# Montana register map
Vendor: ONSemiconductor; Series: Montana Series; File version: 1.0
CPU: CM33 r0p4, little endian, MPU, FPU, 3 interrupt priority bits
Registers are 32-bit, read-write, reset 0x0 unless marked. A register's access mark holds for its fields unless they carry their own. Offsets are from the block's base; [hi:lo] are bit positions; {n}, {i} and the like mark numbered series.

## GPIO — GPIO Interface and Digital Pad control
Base 0x40000A00
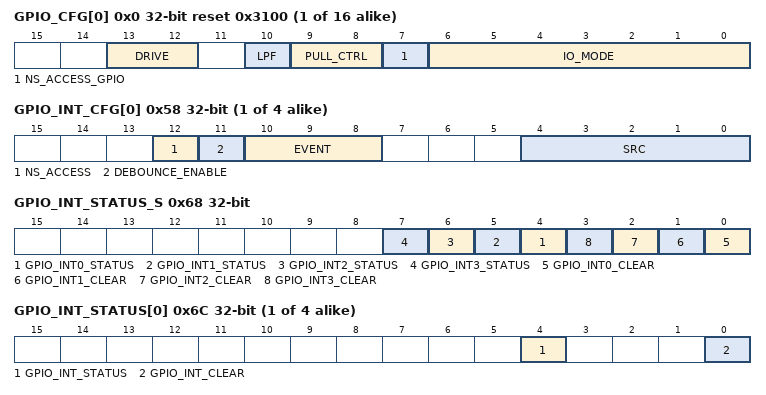
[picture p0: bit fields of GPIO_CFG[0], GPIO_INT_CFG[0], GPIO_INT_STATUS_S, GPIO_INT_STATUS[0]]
{0x0+4i} GPIO_CFG[{i}] (i=0..15) reset 0x3100 — Digital IO Configuration
  [13:12] DRIVE — Drive strength configuration
    0=GPIO_2X_DRIVE (2x drive strength); 1=GPIO_3X_DRIVE (3x drive strength); 2=GPIO_5X_DRIVE (5x drive strength); 3=GPIO_6X_DRIVE (6x drive strength)
  [10] LPF — Low Pass Filter enable
    0=GPIO_LPF_DISABLE (Disable low pass filter); 1=GPIO_LPF_ENABLE (Enable low pass filter)
  [9:8] PULL_CTRL — Pull selection
    0=GPIO_NO_PULL (No pull selected); 1=GPIO_WEAK_PULL_UP (Weak pull-up selected); 2=GPIO_WEAK_PULL_DOWN (Weak pull-down selected); 3=GPIO_STRONG_PULL_UP (Strong pull-up selected)
  [7] NS_ACCESS_GPIO — Non-Secure code can use GPIO
    0=NS_CANNOT_USE_GPIO (Non-Secure code cannot use this GPIO); 1=NS_CAN_USE_GPIO (Non-Secure code can use this GPIO)
  [6:0] IO_MODE — IO mode selection
    0=GPIO_MODE_DISABLE (Disable); 1=GPIO_MODE_INPUT (Input mode); 2=GPIO_MODE_GPIO_IN (GPIO input mode); 3=GPIO_MODE_GPIO_OUT (GPIO output mode (value given by GPIO_OUTPUT_DATA register)); 4=GPIO_MODE_SLOWCLK (Output SLOWCLK (slow clock) signal); 5=GPIO_MODE_SYSCLK (Output SYSCLK (system clock) signal); 6=GPIO_MODE_USRCLK (Output USRCLK (user clock) signal); 7=GPIO_MODE_SPI0_IO0 (Output SPI0_IO0 interface signal (master SERO)); 8=GPIO_MODE_SPI0_IO1 (Output SPI0_IO1 interface signal (slave SERO)); 9=GPIO_MODE_SPI0_IO2 (Output SPI0_IO2 interface signal); 10=GPIO_MODE_SPI0_IO3 (Output SPI0_IO3 interface signal); 11=GPIO_MODE_SPI0_CS (Output SPI0_CS interface signal); 12=GPIO_MODE_SPI0_CLK (Output SPI0_CLK interface signal); 13=GPIO_MODE_UART0_TX (Output UART0_TX0 interface signal); 14=GPIO_MODE_I2C0_SCL (Output I2C0 SCL interface signal (open collector)); 15=GPIO_MODE_I2C0_SDA (Output I2C0 SDA interface signal (open collector)); 16=GPIO_MODE_RFCLK (Output RFCLK signal); 17=GPIO_MODE_RCCLK (Output RCCLK signal); 18=GPIO_MODE_SWCLK_DIV (Output of SWCLK divider signal); 19=GPIO_MODE_STANDBYCLK (Output STANDBYCLK signal); 20=GPIO_MODE_BB_TX_DATA (Output baseband controller TX data signal); 21=GPIO_MODE_BB_TX_DATA_VALID (Output baseband controller TX data valid signal); 22=GPIO_MODE_BB_SPI_CSN (Output baseband controller SPI_CSN signal); 23=GPIO_MODE_BB_SPI_CLK (Output baseband controller SPI_CLK signal); 24=GPIO_MODE_BB_SPI_MOSI (Output baseband controller SPI_MOSI signal); {v}=GPIO_MODE_BB_DBG_{v-25} (Output baseband controller debug port (bit {v-25}) signal) (v=25..32); 33=GPIO_MODE_BB_BLE_SYNC (Output baseband controller wlan coex signal sync); 34=GPIO_MODE_BB_BLE_IN_PROCESS (Output baseband controller wlan coex signal in_process); 35=GPIO_MODE_BB_BLE_TX (Output baseband controller wlan coex signal Tx); 36=GPIO_MODE_BB_BLE_RX (Output baseband controller wlan coex signal Rx); {v}=GPIO_MODE_BB_BLE_PTI_{v-37} (Output baseband controller wlan coex signal PTI (bit {v-37})) (v=37..40); 41=GPIO_MODE_BB_ANT_SW_EN (Output baseband controller antenna switch enable); {v}=GPIO_MODE_BB_ANT_SW_{v-42} (Output baseband controller antenna switch (bit {v-42})) (v=42..48); 49=GPIO_MODE_BB_CTE_MODE (Output baseband controller CTE mode); 50=GPIO_MODE_BB_CTE_SAMPLE_P (Output baseband controller CTE sample pulse); 51=GPIO_MODE_RF_SPI_MISO (Output RF front-end SPI_MISO interface signal); 52=GPIO_MODE_RF_GPIO0 (Output RF front-end GPIO0 output signal (RX_DATA)); 53=GPIO_MODE_RF_GPIO1 (Output RF front-end GPIO1 output signal (RX_CLK)); 54=GPIO_MODE_RF_GPIO2 (Output RF front-end GPIO2 output signal (SYNC_P)); {v}=GPIO_MODE_RF_GPIO{v-52} (Output RF front-end GPIO{v-52} output signal) (v=55..61); 62=GPIO_MODE_RF_IQ_DATA_P (Output RF front-end IQ data pulse signal); {v}=GPIO_MODE_RF_I_DATA_{v-63} (Output RF front-end I data (bit {v-63})) (v=63..70); {v}=GPIO_MODE_RF_Q_DATA_{v-71} (Output RF front-end Q data (bit {v-71})) (v=71..78); {v}=GPIO_MODE_RF_ANT_SW_{v-79} (Output RF front-end antenna switch (bit {v-79})) (v=79..82); 83=GPIO_MODE_TOF_START (Output Time Of Flight timer start trigger); 84=GPIO_MODE_TOF_STOP (Output Time Of Flight timer stop trigger)
0x40 GPIO_INPUT_DATA ro — Digital IOs Input Data State
  [15:0] DATA — GPIO[15:0] read data
    0=GPIO0_IN_LOW (GPIO pad is low); 0=GPIO1_IN_LOW (GPIO pad is low); 0=GPIO2_IN_LOW (GPIO pad is low); 0=GPIO3_IN_LOW (GPIO pad is low); 0=GPIO4_IN_LOW (GPIO pad is low); 0=GPIO5_IN_LOW (GPIO pad is low); 0=GPIO6_IN_LOW (GPIO pad is low); 0=GPIO7_IN_LOW (GPIO pad is low); 0=GPIO8_IN_LOW (GPIO pad is low); 0=GPIO9_IN_LOW (GPIO pad is low); 0=GPIO10_IN_LOW (GPIO pad is low); 0=GPIO11_IN_LOW (GPIO pad is low); 0=GPIO12_IN_LOW (GPIO pad is low); 0=GPIO13_IN_LOW (GPIO pad is low); 0=GPIO14_IN_LOW (GPIO pad is low); 0=GPIO15_IN_LOW (GPIO pad is low); 1=GPIO0_IN_HIGH (GPIO pad is high); 2=GPIO1_IN_HIGH (GPIO pad is high); 4=GPIO2_IN_HIGH (GPIO pad is high); 8=GPIO3_IN_HIGH (GPIO pad is high); 16=GPIO4_IN_HIGH (GPIO pad is high); 32=GPIO5_IN_HIGH (GPIO pad is high); 64=GPIO6_IN_HIGH (GPIO pad is high); 128=GPIO7_IN_HIGH (GPIO pad is high); 0x100=GPIO8_IN_HIGH (GPIO pad is high); 0x200=GPIO9_IN_HIGH (GPIO pad is high); 0x400=GPIO10_IN_HIGH (GPIO pad is high); 0x800=GPIO11_IN_HIGH (GPIO pad is high); 0x1000=GPIO12_IN_HIGH (GPIO pad is high); 0x2000=GPIO13_IN_HIGH (GPIO pad is high); 0x4000=GPIO14_IN_HIGH (GPIO pad is high); 0x8000=GPIO15_IN_HIGH (GPIO pad is high)
0x44 GPIO_OUTPUT_DATA
  [15:0] DATA — GPIO[15:0] output data
    0=GPIO0_OUT_LOW (Set the GPIO pad to low if IO_MODE is GPIO); 0=GPIO1_OUT_LOW (Set the GPIO pad to low if IO_MODE is GPIO); 0=GPIO2_OUT_LOW (Set the GPIO pad to low if IO_MODE is GPIO); 0=GPIO3_OUT_LOW (Set the GPIO pad to low if IO_MODE is GPIO); 0=GPIO4_OUT_LOW (Set the GPIO pad to low if IO_MODE is GPIO); 0=GPIO5_OUT_LOW (Set the GPIO pad to low if IO_MODE is GPIO); 0=GPIO6_OUT_LOW (Set the GPIO pad to low if IO_MODE is GPIO); 0=GPIO7_OUT_LOW (Set the GPIO pad to low if IO_MODE is GPIO); 0=GPIO8_OUT_LOW (Set the GPIO pad to low if IO_MODE is GPIO); 0=GPIO9_OUT_LOW (Set the GPIO pad to low if IO_MODE is GPIO); 0=GPIO10_OUT_LOW (Set the GPIO pad to low if IO_MODE is GPIO); 0=GPIO11_OUT_LOW (Set the GPIO pad to low if IO_MODE is GPIO); 0=GPIO12_OUT_LOW (Set the GPIO pad to low if IO_MODE is GPIO); 0=GPIO13_OUT_LOW (Set the GPIO pad to low if IO_MODE is GPIO); 0=GPIO14_OUT_LOW (Set the GPIO pad to low if IO_MODE is GPIO); 0=GPIO15_OUT_LOW (Set the GPIO pad to low if IO_MODE is GPIO); 1=GPIO0_OUT_HIGH (Set the GPIO pad to high if IO_MODE is GPIO); 2=GPIO1_OUT_HIGH (Set the GPIO pad to high if IO_MODE is GPIO); 4=GPIO2_OUT_HIGH (Set the GPIO pad to high if IO_MODE is GPIO); 8=GPIO3_OUT_HIGH (Set the GPIO pad to high if IO_MODE is GPIO); 16=GPIO4_OUT_HIGH (Set the GPIO pad to high if IO_MODE is GPIO); 32=GPIO5_OUT_HIGH (Set the GPIO pad to high if IO_MODE is GPIO); 64=GPIO6_OUT_HIGH (Set the GPIO pad to high if IO_MODE is GPIO); 128=GPIO7_OUT_HIGH (Set the GPIO pad to high if IO_MODE is GPIO); 0x100=GPIO8_OUT_HIGH (Set the GPIO pad to high if IO_MODE is GPIO); 0x200=GPIO9_OUT_HIGH (Set the GPIO pad to high if IO_MODE is GPIO); 0x400=GPIO10_OUT_HIGH (Set the GPIO pad to high if IO_MODE is GPIO); 0x800=GPIO11_OUT_HIGH (Set the GPIO pad to high if IO_MODE is GPIO); 0x1000=GPIO12_OUT_HIGH (Set the GPIO pad to high if IO_MODE is GPIO); 0x2000=GPIO13_OUT_HIGH (Set the GPIO pad to high if IO_MODE is GPIO); 0x4000=GPIO14_OUT_HIGH (Set the GPIO pad to high if IO_MODE is GPIO); 0x8000=GPIO15_OUT_HIGH (Set the GPIO pad to high if IO_MODE is GPIO)
0x48 GPIO_OUTPUT_DATA_SET reset not defined
  [15:0] GPIO wo — GPIO[15:0] output data set
    1=GPIO0_SET (Set the GPIO output data high); 2=GPIO1_SET (Set the GPIO output data high); 4=GPIO2_SET (Set the GPIO output data high); 8=GPIO3_SET (Set the GPIO output data high); 16=GPIO4_SET (Set the GPIO output data high); 32=GPIO5_SET (Set the GPIO output data high); 64=GPIO6_SET (Set the GPIO output data high); 128=GPIO7_SET (Set the GPIO output data high); 0x100=GPIO8_SET (Set the GPIO output data high); 0x200=GPIO9_SET (Set the GPIO output data high); 0x400=GPIO10_SET (Set the GPIO output data high); 0x800=GPIO11_SET (Set the GPIO output data high); 0x1000=GPIO12_SET (Set the GPIO output data high); 0x2000=GPIO13_SET (Set the GPIO output data high); 0x4000=GPIO14_SET (Set the GPIO output data high); 0x8000=GPIO15_SET (Set the GPIO output data high)
0x4C GPIO_OUTPUT_DATA_CLR reset not defined — GPIO Output Data Clear
  [15:0] GPIO wo — GPIO[15:0] output data clear
    1=GPIO0_CLR (Set the GPIO output data low); 2=GPIO1_CLR (Set the GPIO output data low); 4=GPIO2_CLR (Set the GPIO output data low); 8=GPIO3_CLR (Set the GPIO output data low); 16=GPIO4_CLR (Set the GPIO output data low); 32=GPIO5_CLR (Set the GPIO output data low); 64=GPIO6_CLR (Set the GPIO output data low); 128=GPIO7_CLR (Set the GPIO output data low); 0x100=GPIO8_CLR (Set the GPIO output data low); 0x200=GPIO9_CLR (Set the GPIO output data low); 0x400=GPIO10_CLR (Set the GPIO output data low); 0x800=GPIO11_CLR (Set the GPIO output data low); 0x1000=GPIO12_CLR (Set the GPIO output data low); 0x2000=GPIO13_CLR (Set the GPIO output data low); 0x4000=GPIO14_CLR (Set the GPIO output data low); 0x8000=GPIO15_CLR (Set the GPIO output data low)
0x50 GPIO_DIR — Digital IOs Direction State
  [15:0] GPIO ro — Get GPIO[15:0] direction
    0=GPIO0_STATUS_IN (GPIO is an input); 0=GPIO1_STATUS_IN (GPIO is an input); 0=GPIO2_STATUS_IN (GPIO is an input); 0=GPIO3_STATUS_IN (GPIO is an input); 0=GPIO4_STATUS_IN (GPIO is an input); 0=GPIO5_STATUS_IN (GPIO is an input); 0=GPIO6_STATUS_IN (GPIO is an input); 0=GPIO7_STATUS_IN (GPIO is an input); 0=GPIO8_STATUS_IN (GPIO is an input); 0=GPIO9_STATUS_IN (GPIO is an input); 0=GPIO10_STATUS_IN (GPIO is an input); 0=GPIO11_STATUS_IN (GPIO is an input); 0=GPIO12_STATUS_IN (GPIO is an input); 0=GPIO13_STATUS_IN (GPIO is an input); 0=GPIO14_STATUS_IN (GPIO is an input); 0=GPIO15_STATUS_IN (GPIO is an input); 1=GPIO0_STATUS_OUT (GPIO is an output); 2=GPIO1_STATUS_OUT (GPIO is an output); 4=GPIO2_STATUS_OUT (GPIO is an output); 8=GPIO3_STATUS_OUT (GPIO is an output); 16=GPIO4_STATUS_OUT (GPIO is an output); 32=GPIO5_STATUS_OUT (GPIO is an output); 64=GPIO6_STATUS_OUT (GPIO is an output); 128=GPIO7_STATUS_OUT (GPIO is an output); 0x100=GPIO8_STATUS_OUT (GPIO is an output); 0x200=GPIO9_STATUS_OUT (GPIO is an output); 0x400=GPIO10_STATUS_OUT (GPIO is an output); 0x800=GPIO11_STATUS_OUT (GPIO is an output); 0x1000=GPIO12_STATUS_OUT (GPIO is an output); 0x2000=GPIO13_STATUS_OUT (GPIO is an output); 0x4000=GPIO14_STATUS_OUT (GPIO is an output); 0x8000=GPIO15_STATUS_OUT (GPIO is an output)
  [15:0] GPIO wo — Set GPIO[15:0] GPIO direction (only in GPIO_MODE_GPIO_x)
    0=GPIO0_DIR_IN (Set GPIO to input if GPIO_MODE_GPIO_IN_x); 0=GPIO1_DIR_IN (Set GPIO to input if GPIO_MODE_GPIO_IN_x); 0=GPIO2_DIR_IN (Set GPIO to input if GPIO_MODE_GPIO_IN_x); 0=GPIO3_DIR_IN (Set GPIO to input if GPIO_MODE_GPIO_IN_x); 0=GPIO4_DIR_IN (Set GPIO to input if GPIO_MODE_GPIO_IN_x); 0=GPIO5_DIR_IN (Set GPIO to input if GPIO_MODE_GPIO_IN_x); 0=GPIO6_DIR_IN (Set GPIO to input if GPIO_MODE_GPIO_IN_x); 0=GPIO7_DIR_IN (Set GPIO to input if GPIO_MODE_GPIO_IN_x); 0=GPIO8_DIR_IN (Set GPIO to input if GPIO_MODE_GPIO_IN_x); 0=GPIO9_DIR_IN (Set GPIO to input if GPIO_MODE_GPIO_IN_x); 0=GPIO10_DIR_IN (Set GPIO to input if GPIO_MODE_GPIO_IN_x); 0=GPIO11_DIR_IN (Set GPIO to input if GPIO_MODE_GPIO_IN_x); 0=GPIO12_DIR_IN (Set GPIO to input if GPIO_MODE_GPIO_IN_x); 0=GPIO13_DIR_IN (Set GPIO to input if GPIO_MODE_GPIO_IN_x); 0=GPIO14_DIR_IN (Set GPIO to input if GPIO_MODE_GPIO_IN_x); 0=GPIO15_DIR_IN (Set GPIO to input if GPIO_MODE_GPIO_IN_x); 1=GPIO0_DIR_OUT (Set GPIO to output if GPIO_MODE_GPIO_OUT_x); 2=GPIO1_DIR_OUT (Set GPIO to output if GPIO_MODE_GPIO_OUT_x); 4=GPIO2_DIR_OUT (Set GPIO to output if GPIO_MODE_GPIO_OUT_x); 8=GPIO3_DIR_OUT (Set GPIO to output if GPIO_MODE_GPIO_OUT_x); 16=GPIO4_DIR_OUT (Set GPIO to output if GPIO_MODE_GPIO_OUT_x); 32=GPIO5_DIR_OUT (Set GPIO to output if GPIO_MODE_GPIO_OUT_x); 64=GPIO6_DIR_OUT (Set GPIO to output if GPIO_MODE_GPIO_OUT_x); 128=GPIO7_DIR_OUT (Set GPIO to output if GPIO_MODE_GPIO_OUT_x); 0x100=GPIO8_DIR_OUT (Set GPIO to output if GPIO_MODE_GPIO_OUT_x); 0x200=GPIO9_DIR_OUT (Set GPIO to output if GPIO_MODE_GPIO_OUT_x); 0x400=GPIO10_DIR_OUT (Set GPIO to output if GPIO_MODE_GPIO_OUT_x); 0x800=GPIO11_DIR_OUT (Set GPIO to output if GPIO_MODE_GPIO_OUT_x); 0x1000=GPIO12_DIR_OUT (Set GPIO to output if GPIO_MODE_GPIO_OUT_x); 0x2000=GPIO13_DIR_OUT (Set GPIO to output if GPIO_MODE_GPIO_OUT_x); 0x4000=GPIO14_DIR_OUT (Set GPIO to output if GPIO_MODE_GPIO_OUT_x); 0x8000=GPIO15_DIR_OUT (Set GPIO to output if GPIO_MODE_GPIO_OUT_x)
0x54 GPIO_MODE ro — Digital IOs Mode State
  [15:0] GPIO — GPIO[15:0] mode
    0=GPIO0_IS_NOT_GPIO_MODE (This GPIO is not configured as a CM33 controlled GPIO); 0=GPIO1_IS_NOT_GPIO_MODE (This GPIO is not configured as a CM33 controlled GPIO); 0=GPIO2_IS_NOT_GPIO_MODE (This GPIO is not configured as a CM33 controlled GPIO); 0=GPIO3_IS_NOT_GPIO_MODE (This GPIO is not configured as a CM33 controlled GPIO); 0=GPIO4_IS_NOT_GPIO_MODE (This GPIO is not configured as a CM33 controlled GPIO); 0=GPIO5_IS_NOT_GPIO_MODE (This GPIO is not configured as a CM33 controlled GPIO); 0=GPIO6_IS_NOT_GPIO_MODE (This GPIO is not configured as a CM33 controlled GPIO); 0=GPIO7_IS_NOT_GPIO_MODE (This GPIO is not configured as a CM33 controlled GPIO); 0=GPIO8_IS_NOT_GPIO_MODE (This GPIO is not configured as a CM33 controlled GPIO); 0=GPIO9_IS_NOT_GPIO_MODE (This GPIO is not configured as a CM33 controlled GPIO); 0=GPIO10_IS_NOT_GPIO_MODE (This GPIO is not configured as a CM33 controlled GPIO); 0=GPIO11_IS_NOT_GPIO_MODE (This GPIO is not configured as a CM33 controlled GPIO); 0=GPIO12_IS_NOT_GPIO_MODE (This GPIO is not configured as a CM33 controlled GPIO); 0=GPIO13_IS_NOT_GPIO_MODE (This GPIO is not configured as a CM33 controlled GPIO); 0=GPIO14_IS_NOT_GPIO_MODE (This GPIO is not configured as a CM33 controlled GPIO); 0=GPIO15_IS_NOT_GPIO_MODE (This GPIO is not configured as a CM33 controlled GPIO); 1=GPIO0_IS_GPIO_MODE (This GPIO is configured as a CM33 controlled GPIO); 2=GPIO1_IS_GPIO_MODE (This GPIO is configured as a CM33 controlled GPIO); 4=GPIO2_IS_GPIO_MODE (This GPIO is configured as a CM33 controlled GPIO); 8=GPIO3_IS_GPIO_MODE (This GPIO is configured as a CM33 controlled GPIO); 16=GPIO4_IS_GPIO_MODE (This GPIO is configured as a CM33 controlled GPIO); 32=GPIO5_IS_GPIO_MODE (This GPIO is configured as a CM33 controlled GPIO); 64=GPIO6_IS_GPIO_MODE (This GPIO is configured as a CM33 controlled GPIO); 128=GPIO7_IS_GPIO_MODE (This GPIO is configured as a CM33 controlled GPIO); 0x100=GPIO8_IS_GPIO_MODE (This GPIO is configured as a CM33 controlled GPIO); 0x200=GPIO9_IS_GPIO_MODE (This GPIO is configured as a CM33 controlled GPIO); 0x400=GPIO10_IS_GPIO_MODE (This GPIO is configured as a CM33 controlled GPIO); 0x800=GPIO11_IS_GPIO_MODE (This GPIO is configured as a CM33 controlled GPIO); 0x1000=GPIO12_IS_GPIO_MODE (This GPIO is configured as a CM33 controlled GPIO); 0x2000=GPIO13_IS_GPIO_MODE (This GPIO is configured as a CM33 controlled GPIO); 0x4000=GPIO14_IS_GPIO_MODE (This GPIO is configured as a CM33 controlled GPIO); 0x8000=GPIO15_IS_GPIO_MODE (This GPIO is configured as a CM33 controlled GPIO)
{0x58+4i} GPIO_INT_CFG[{i}] (i=0..3) — GPIO Interrupt Configuration
  [12] NS_ACCESS — Non-Secure code can access this GPIO_INT
    0=NS_CANNOT_ACCESS_GPIO_INT (Non-Secure code cannot access the GPIO_INT); 1=NS_CAN_ACCESS_GPIO_INT (Non-Secure code can access the GPIO_INT)
  [11] DEBOUNCE_ENABLE — Interrupt button debounce filter enable/disable
    0=GPIO_DEBOUNCE_DISABLE (Button debounce filter disabled); 1=GPIO_DEBOUNCE_ENABLE (Button debounce filter enabled)
  [10:8] EVENT — Interrupt event configuration
    0=GPIO_EVENT_NONE (Interrupt not triggered); 1=GPIO_EVENT_HIGH_LEVEL (Interrupt triggered on high state); 2=GPIO_EVENT_LOW_LEVEL (Interrupt triggered on low state); 3=GPIO_EVENT_RISING_EDGE (Interrupt triggered on rising edge); 4=GPIO_EVENT_FALLING_EDGE (Interrupt triggered on falling edge); 5=GPIO_EVENT_TRANSITION (Interrupt triggered on any edge)
  [4:0] SRC — Interrupt input selection
    {v}=GPIO_SRC_GPIO_{v} (Select GPIO[{v}] as source) (v=0..15); 16=GPIO_SRC_WAKEUP (Select WAKEUP as source)
0x68 GPIO_INT_STATUS_S (reset mask 0xF0) — GPIO Interrupt Status
  [n+4] GPIO_INT{n}_STATUS ro (n=0..3) — GPIO interrupt {n} status
    0=GPIO_INT{n}_FALSE (Interrupt {n} not triggered); 1=GPIO_INT{n}_TRUE (Interrupt {n} triggered)
  [n] GPIO_INT{n}_CLEAR wo (n=0..3) — GPIO interrupt {n} clear
    1=GPIO_INT{n}_CLEAR (Interrupt {n} clear)
{0x6C+4i} GPIO_INT_STATUS[{i}] (i=0..3) (reset mask 0x10) — GPIO Interrupt Status
  [4] GPIO_INT_STATUS ro — GPIO interrupt status
    0=GPIO_INT_FALSE (Interrupt not triggered); 1=GPIO_INT_TRUE (Interrupt triggered)
  [0] GPIO_INT_CLEAR wo — GPIO interrupt clear
    1=GPIO_INT_CLEAR (Interrupt clear)
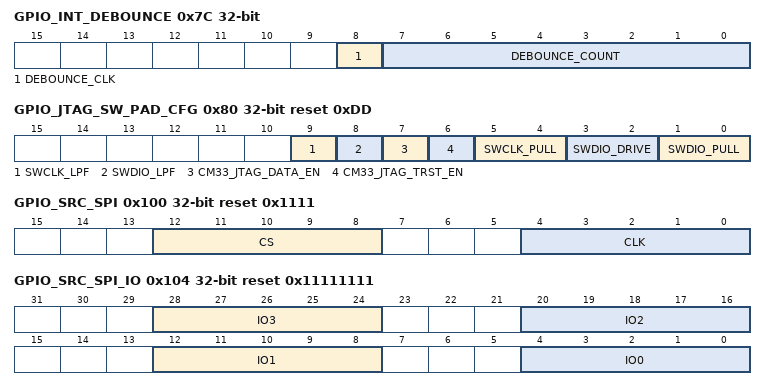
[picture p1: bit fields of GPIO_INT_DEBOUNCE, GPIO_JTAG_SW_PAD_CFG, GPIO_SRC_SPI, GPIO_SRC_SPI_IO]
0x7C GPIO_INT_DEBOUNCE — GPIO Interrupt Button Debounce Filter Time Configuration
  [8] DEBOUNCE_CLK — Interrupt button debounce filter clock
    0=GPIO_DEBOUNCE_SLOWCLK_DIV32 (Button debounce filter runs on SLOWCLK divided by 32); 1=GPIO_DEBOUNCE_SLOWCLK_DIV1024 (Button debounce filter runs on SLOWCLK divided by 1024)
  [7:0] DEBOUNCE_COUNT — Interrupt button debounce filter count
0x80 GPIO_JTAG_SW_PAD_CFG reset 0xDD — JTAG / SW Pad Configuration Register
  [9] SWCLK_LPF — SWCLK Low-Pass-Filter enable / disable
    0=SWCLK_LPF_DISABLED (Disable low pass filter); 1=SWCLK_LPF_ENABLED (Enable low pass filter)
  [8] SWDIO_LPF — SWDIO Low-Pass-Filter enable / disable
    0=SWDIO_LPF_DISABLED (Disable low pass filter); 1=SWDIO_LPF_ENABLED (Enable low pass filter)
  [7] CM33_JTAG_DATA_EN — CM33 JTAG on GPIO[3:2]
    0=CM33_JTAG_DATA_DISABLED (CM33 JTAG data (TDI & TDO) not available on GPIO[3:2]); 1=CM33_JTAG_DATA_ENABLED (CM33 JTAG data (TDI & TDO) connected through GPIO[3:2])
  [6] CM33_JTAG_TRST_EN — CM33 JTAG TRST on GPIO4
    0=CM33_JTAG_TRST_DISABLED (CM33 JTAG TRST not available on GPIO4); 1=CM33_JTAG_TRST_ENABLED (CM33 JTAG TRST connected through GPIO4)
  [5:4] SWCLK_PULL — SWCLK pull-up enable / disable
    0=SWCLK_NO_PULL (No pull selected); 1=SWCLK_WEAK_PULL_UP (Weak pull-up selected); 2=SWCLK_WEAK_PULL_DOWN (Weak pull-down selected); 3=SWCLK_STRONG_PULL_UP (Strong pull-up selected)
  [3:2] SWDIO_DRIVE — SWDIO drive strength
    0=SWDIO_2X_DRIVE (2x drive strength); 1=SWDIO_3X_DRIVE (3x drive strength); 2=SWDIO_5X_DRIVE (5x drive strength); 3=SWDIO_6X_DRIVE (6x drive strength)
  [1:0] SWDIO_PULL — SWDIO pull-up enable / disable
    0=SWDIO_NO_PULL (No pull selected); 1=SWDIO_WEAK_PULL_UP (Weak pull-up selected); 2=SWDIO_WEAK_PULL_DOWN (Weak pull-down selected); 3=SWDIO_STRONG_PULL_UP (Strong pull-up selected)
0x8C GPIO_PAD_CFG — Global Pads Configuration Register
  [0] DRIVE — Drive strength configuration (scales the individual drive strengths)
    0=PAD_LOW_DRIVE (All pad regular drive strengths (allowed for all VDDO voltages)); 1=PAD_HIGH_DRIVE (All pad drive strengths increased by ~50 percent (only allowed for VDDO up to 2.7 V))
0x100 GPIO_SRC_SPI reset 0x1111 — SPI Interface Input Selection
  [12:8] CS — SPI_CS input selection
    {v}=SPI_CS_SRC_GPIO_{v} (Select GPIO[{v}] as source) (v=0..15); 16=SPI_CS_SRC_CONST_LOW (Select constant low as source); 17=SPI_CS_SRC_CONST_HIGH (Select constant high as source)
  [4:0] CLK — SPI_CLK input selection
    {v}=SPI_CLK_SRC_GPIO_{v} (Select GPIO[{v}] as source) (v=0..15); 16=SPI_CLK_SRC_CONST_LOW (Select constant low as source); 17=SPI_CLK_SRC_CONST_HIGH (Select constant high as source)
0x104 GPIO_SRC_SPI_IO reset 0x11111111 — SPI Interface IO Selection
  [28:24] IO3 — SPI_IO3 input selection
    {v}=SPI_IO3_SRC_GPIO_{v} (Select GPIO[{v}] as source) (v=0..15); 16=SPI_IO3_SRC_CONST_LOW (Select constant low as source); 17=SPI_IO3_SRC_CONST_HIGH (Select constant high as source)
  [20:16] IO2 — SPI_IO2 input selection
    {v}=SPI_IO2_SRC_GPIO_{v} (Select GPIO[{v}] as source) (v=0..15); 16=SPI_IO2_SRC_CONST_LOW (Select constant low as source); 17=SPI_IO2_SRC_CONST_HIGH (Select constant high as source)
  [12:8] IO1 — SPI_IO1 input selection (master SERI)
    {v}=SPI_IO1_SRC_GPIO_{v} (Select GPIO[{v}] as source) (v=0..15); 16=SPI_IO1_SRC_CONST_LOW (Select constant low as source); 17=SPI_IO1_SRC_CONST_HIGH (Select constant high as source)
  [4:0] IO0 — SPI_IO0 input selection (slave SERI)
    {v}=SPI_IO0_SRC_GPIO_{v} (Select GPIO[{v}] as source) (v=0..15); 16=SPI_IO0_SRC_CONST_LOW (Select constant low as source); 17=SPI_IO0_SRC_CONST_HIGH (Select constant high as source)
0x108 GPIO_SRC_UART reset 0x11 — UART Interface Input Selection
  [4:0] RX — UART_RX input selection
    {v}=UART_RX_SRC_GPIO_{v} (Select GPIO[{v}] as source) (v=0..15); 16=UART_RX_SRC_CONST_LOW (Select constant low as source); 17=UART_RX_SRC_CONST_HIGH (Select constant high as source)
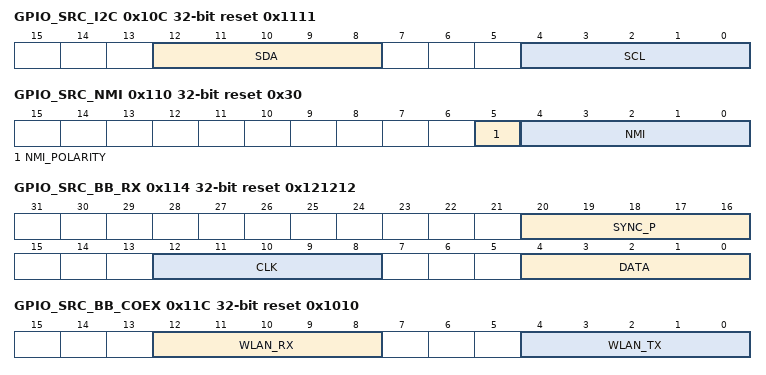
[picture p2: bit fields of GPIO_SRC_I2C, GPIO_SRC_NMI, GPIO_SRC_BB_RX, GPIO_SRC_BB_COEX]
0x10C GPIO_SRC_I2C reset 0x1111 — I2C Input Selection
  [12:8] SDA — SDA input selection
    {v}=I2C_SDA_SRC_GPIO_{v} (Select GPIO[{v}] as source) (v=0..15); 16=I2C_SDA_SRC_CONST_LOW (Select constant low as source); 17=I2C_SDA_SRC_CONST_HIGH (Select constant high as source)
  [4:0] SCL — SCL input selection
    {v}=I2C_SCL_SRC_GPIO_{v} (Select GPIO[{v}] as source) (v=0..15); 16=I2C_SCL_SRC_CONST_LOW (Select constant low as source); 17=I2C_SCL_SRC_CONST_HIGH (Select constant high as source)
0x110 GPIO_SRC_NMI reset 0x30 — NMI Input Selection
  [5] NMI_POLARITY
    0=NMI_ACTIVE_LOW; 1=NMI_ACTIVE_HIGH
  [4:0] NMI — NMI input selection
    {v}=NMI_SRC_GPIO_{v} (Select GPIO[{v}] as source) (v=0..15); 16=NMI_SRC_CONST_LOW (Select constant low as source); 17=NMI_SRC_CONST_HIGH (Select constant high as source)
0x114 GPIO_SRC_BB_RX reset 0x121212 — Baseband controller RX data and clock input selection
  [20:16] SYNC_P — Baseband controller interface SYNC_P input selection
    0=BB_RX_SYNC_P_SRC_GPIO_0 (Select GPIO[0] as source); 1=BB_RX_SYNC_P_SRC_GPIO_1 (Select GPIO[1] as source); 2=BB_RX_SYNC_P_SRC_GPIO_2 (Select GPIO[5] as source); {v}=BB_RX_SYNC_P_SRC_GPIO_{v} (Select GPIO[{v}] as source) (v=3..15); 16=BB_RX_SYNC_P_SRC_CONST_LOW (Select constant low as source); 17=BB_RX_SYNC_P_SRC_CONST_HIGH (Select constant high as source); 18=BB_RX_SYNC_P_SRC_RF_GPIO2 (Select RF front-end GPIO2 output (RX_SYNC_P) as source)
  [12:8] CLK — Baseband controller RX clock input selection
    {v}=BB_RX_CLK_SRC_GPIO_{v} (Select GPIO[{v}] as source) (v=0..15); 16=BB_RX_CLK_SRC_CONST_LOW (Select constant low as source); 17=BB_RX_CLK_SRC_CONST_HIGH (Select constant high as source); 18=BB_RX_CLK_SRC_RF_GPIO1 (Select RF front-end GPIO1 output (RX_CLK) as source)
  [4:0] DATA — Baseband controller RX data input selection
    {v}=BB_RX_DATA_SRC_GPIO_{v} (Select GPIO[{v}] as source) (v=0..15); 16=BB_RX_DATA_SRC_CONST_LOW (Select constant low as source); 17=BB_RX_DATA_SRC_CONST_HIGH (Select constant high as source); 18=BB_RX_DATA_SRC_RF_GPIO0 (Select RF front-end GPIO0 output (RX_DATA) as source)
0x118 GPIO_SRC_BB_SPI reset 0x12 — Baseband controller SPI input selection
  [4:0] MISO — Baseband controller SPI_MISO input selection
    {v}=BB_SPI_MISO_SRC_GPIO_{v} (Select GPIO[{v}] as source) (v=0..15); 16=BB_SPI_MISO_SRC_CONST_LOW (Select constant low as source); 17=BB_SPI_MISO_SRC_CONST_HIGH (Select constant high as source); 18=BB_SPI_MISO_SRC_RF_SPI_MISO (Select RF front-end SPI_MISO as source)
0x11C GPIO_SRC_BB_COEX reset 0x1010 — Baseband controller WLAN coexistence input selection
  [12:8] WLAN_RX — Baseband controller WLAN_RX input selection
    {v}=BB_WLAN_RX_SRC_GPIO_{v} (Select GPIO[{v}] as source) (v=0..15); 16=BB_WLAN_RX_SRC_CONST_LOW (Select constant low as source); 17=BB_WLAN_RX_SRC_CONST_HIGH (Select constant high as source)
  [4:0] WLAN_TX — Baseband controller WLAN_TX input selection
    {v}=BB_WLAN_TX_SRC_GPIO_{v} (Select GPIO[{v}] as source) (v=0..15); 16=BB_WLAN_TX_SRC_CONST_LOW (Select constant low as source); 17=BB_WLAN_TX_SRC_CONST_HIGH (Select constant high as source)
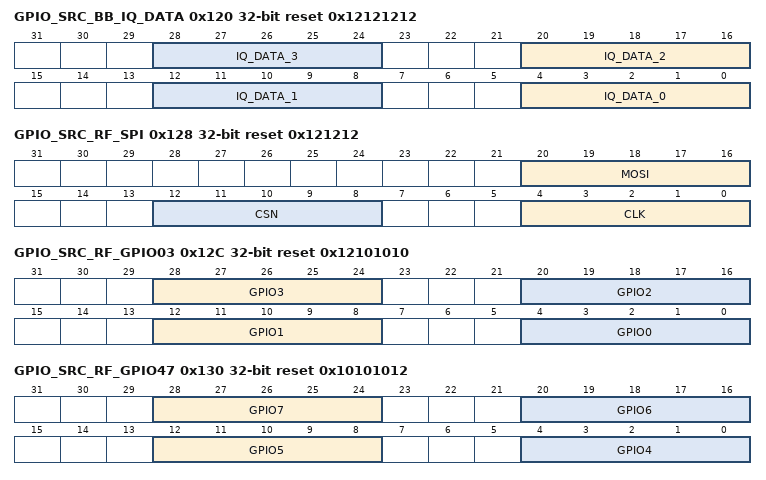
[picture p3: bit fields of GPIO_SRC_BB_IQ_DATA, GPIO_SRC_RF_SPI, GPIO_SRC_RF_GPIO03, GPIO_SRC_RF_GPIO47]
0x120 GPIO_SRC_BB_IQ_DATA reset 0x12121212 — Baseband controller IQ data input selection
  [8n+4:8n] IQ_DATA_{n} (n=0..3) — Baseband controller IQ_DATA_{n} input selection
    {v}=BB_IQ_DATA_{n}_SRC_GPIO_{v} (Select GPIO[{v}] as source) (v=0..15); 16=BB_IQ_DATA_{n}_SRC_CONST_LOW (Select constant low as source); 17=BB_IQ_DATA_{n}_SRC_CONST_HIGH (Select constant high as source); 18=BB_IQ_DATA_{n}_SRC_RF_IQ_DATA_{n} (Select RF front-end IQ_DATA_{n} as source)
0x124 GPIO_SRC_BB_IQ_DATA_P reset 0x12 — Baseband controller IQ data pulse input selection
  [4:0] IQ_DATA_P — Baseband controller IQ_DATA_P input selection
    {v}=BB_IQ_DATA_P_SRC_GPIO_{v} (Select GPIO[{v}] as source) (v=0..15); 16=BB_IQ_DATA_P_SRC_CONST_LOW (Select constant low as source); 17=BB_IQ_DATA_P_SRC_CONST_HIGH (Select constant high as source); 18=BB_IQ_DATA_P_SRC_RF_IQ_DATA_P (Select RF front-end IQ_DATA_P as source)
0x128 GPIO_SRC_RF_SPI reset 0x121212 — RF front-end SPI input selection
  [20:16] MOSI — RF front-end SPI_MOSI input selection
    {v}=RF_SPI_MOSI_SRC_GPIO_{v} (Select GPIO[{v}] as source) (v=0..15); 16=RF_SPI_MOSI_SRC_CONST_LOW (Select constant low as source); 17=RF_SPI_MOSI_SRC_CONST_HIGH (Select constant high as source); 18=RF_SPI_MOSI_SRC_BB_SPI_MOSI (Select baseband controller SPI_MOSI as source)
  [12:8] CSN — RF front-end SPI_CSN input selection
    {v}=RF_SPI_CSN_SRC_GPIO_{v} (Select GPIO[{v}] as source) (v=0..15); 16=RF_SPI_CSN_SRC_CONST_LOW (Select constant low as source); 17=RF_SPI_CSN_SRC_CONST_HIGH (Select constant high as source); 18=RF_SPI_CSN_SRC_BB_SPI_CSN (Select baseband controller SPI_CSN as source)
  [4:0] CLK — RF front-end SPI_CLK input selection
    {v}=RF_SPI_CLK_SRC_GPIO_{v} (Select GPIO[{v}] as source) (v=0..15); 16=RF_SPI_CLK_SRC_CONST_LOW (Select constant low as source); 17=RF_SPI_CLK_SRC_CONST_HIGH (Select constant high as source); 18=RF_SPI_CLK_SRC_BB_SPI_CLK (Select baseband controller SPI_CLK as source)
0x12C GPIO_SRC_RF_GPIO03 reset 0x12101010 — RF front-end GPIOs 0-3 input selection
  [28:24] GPIO3 — RF front-end GPIO3 input selection
    0=RF_GPIO3_SRC_GPIO_0 (Select GPIO[0] as source); 1=RF_GPIO3_SRC_GPIO_1 (Select GPIO[1] as source); 2=RF_GPIO3_SRC_GPIO_2 (Select GPIO[3] as source); {v}=RF_GPIO3_SRC_GPIO_{v} (Select GPIO[{v}] as source) (v=3..15); 16=RF_GPIO3_SRC_CONST_LOW (Select constant low as source); 17=RF_GPIO3_SRC_CONST_HIGH (Select constant high as source); 18=RF_GPIO3_SRC_BB_TX_DATA (Select baseband controller TX_DATA as source)
  [20:16] GPIO2 — RF front-end GPIO2 input selection
    {v}=RF_GPIO2_SRC_GPIO_{v} (Select GPIO[{v}] as source) (v=0..15); 16=RF_GPIO2_SRC_CONST_LOW (Select constant low as source); 17=RF_GPIO2_SRC_CONST_HIGH (Select constant high as source)
  [12:8] GPIO1 — RF front-end GPIO1 input selection
    0=RF_GPIO1_SRC_GPIO_0 (Select GPIO[0] as source); 1=RF_GPIO1_SRC_GPIO_1 (Select GPIO[1] as source); 2=RF_GPIO1_SRC_GPIO_2 (Select GPIO[1] as source); {v}=RF_GPIO1_SRC_GPIO_{v} (Select GPIO[{v}] as source) (v=3..15); 16=RF_GPIO1_SRC_CONST_LOW (Select constant low as source); 17=RF_GPIO1_SRC_CONST_HIGH (Select constant high as source)
  [4:0] GPIO0 — RF front-end GPIO0 input selection
    0=RF_GPIO0_SRC_GPIO_0 (Select GPIO[0] as source); 1=RF_GPIO0_SRC_GPIO_1 (Select GPIO[1] as source); 2=RF_GPIO0_SRC_GPIO_2 (Select GPIO[0] as source); {v}=RF_GPIO0_SRC_GPIO_{v} (Select GPIO[{v}] as source) (v=3..15); 16=RF_GPIO0_SRC_CONST_LOW (Select constant low as source); 17=RF_GPIO0_SRC_CONST_HIGH (Select constant high as source)
0x130 GPIO_SRC_RF_GPIO47 reset 0x10101012 — RF front-end GPIOs 4-7 input selection
  [28:24] GPIO7 — RF front-end GPIO7 input selection
    0=RF_GPIO7_SRC_GPIO_0 (Select GPIO[0] as source); 1=RF_GPIO7_SRC_GPIO_1 (Select GPIO[1] as source); 2=RF_GPIO7_SRC_GPIO_2 (Select GPIO[5] as source); {v}=RF_GPIO7_SRC_GPIO_{v} (Select GPIO[{v}] as source) (v=3..15); 16=RF_GPIO7_SRC_CONST_LOW (Select constant low as source); 17=RF_GPIO7_SRC_CONST_HIGH (Select constant high as source)
  [20:16] GPIO6 — RF front-end GPIO6 input selection
    0=RF_GPIO6_SRC_GPIO_0 (Select GPIO[0] as source); 1=RF_GPIO6_SRC_GPIO_1 (Select GPIO[1] as source); 2=RF_GPIO6_SRC_GPIO_2 (Select GPIO[5] as source); {v}=RF_GPIO6_SRC_GPIO_{v} (Select GPIO[{v}] as source) (v=3..15); 16=RF_GPIO6_SRC_CONST_LOW (Select constant low as source); 17=RF_GPIO6_SRC_CONST_HIGH (Select constant high as source)
  [12:8] GPIO5 — RF front-end GPIO5 input selection
    0=RF_GPIO5_SRC_GPIO_0 (Select GPIO[0] as source); 1=RF_GPIO5_SRC_GPIO_1 (Select GPIO[1] as source); 2=RF_GPIO5_SRC_GPIO_2 (Select GPIO[5] as source); {v}=RF_GPIO5_SRC_GPIO_{v} (Select GPIO[{v}] as source) (v=3..15); 16=RF_GPIO5_SRC_CONST_LOW (Select constant low as source); 17=RF_GPIO5_SRC_CONST_HIGH (Select constant high as source)
  [4:0] GPIO4 — RE front-end GPIO4 input selection
    0=RF_GPIO4_SRC_GPIO_0 (Select GPIO[0] as source); 1=RF_GPIO4_SRC_GPIO_1 (Select GPIO[1] as source); 2=RF_GPIO4_SRC_GPIO_2 (Select GPIO[4] as source); {v}=RF_GPIO4_SRC_GPIO_{v} (Select GPIO[{v}] as source) (v=3..15); 16=RF_GPIO4_SRC_CONST_LOW (Select constant low as source); 17=RF_GPIO4_SRC_CONST_HIGH (Select constant high as source); 18=RF_GPIO4_SRC_BB_TX_DATA_VALID (Select baseband controller TX_DATA_VALID as source)
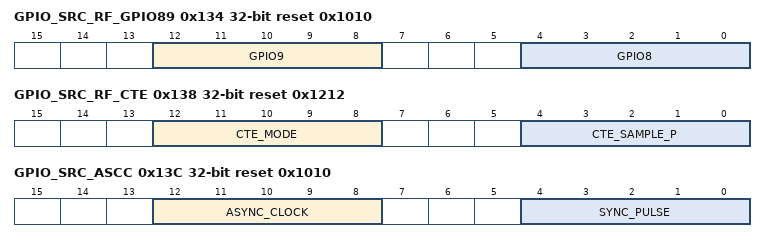
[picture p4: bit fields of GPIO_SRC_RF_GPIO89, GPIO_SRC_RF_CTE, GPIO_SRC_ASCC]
0x134 GPIO_SRC_RF_GPIO89 reset 0x1010 — RF front-end GPIOs 8-9 input selection
  [12:8] GPIO9 — RF front-end GPIO9 input selection
    0=RF_GPIO9_SRC_GPIO_0 (Select GPIO[0] as source); 1=RF_GPIO9_SRC_GPIO_1 (Select GPIO[1] as source); 2=RF_GPIO9_SRC_GPIO_2 (Select GPIO[5] as source); {v}=RF_GPIO9_SRC_GPIO_{v} (Select GPIO[{v}] as source) (v=3..15); 16=RF_GPIO9_SRC_CONST_LOW (Select constant low as source); 17=RF_GPIO9_SRC_CONST_HIGH (Select constant high as source)
  [4:0] GPIO8 — RF front-end GPIO8 input selection
    0=RF_GPIO8_SRC_GPIO_0 (Select GPIO[0] as source); 1=RF_GPIO8_SRC_GPIO_1 (Select GPIO[1] as source); 2=RF_GPIO8_SRC_GPIO_2 (Select GPIO[5] as source); {v}=RF_GPIO8_SRC_GPIO_{v} (Select GPIO[{v}] as source) (v=3..15); 16=RF_GPIO8_SRC_CONST_LOW (Select constant low as source); 17=RF_GPIO8_SRC_CONST_HIGH (Select constant high as source)
0x138 GPIO_SRC_RF_CTE reset 0x1212 — RF front-end CTE input selection
  [12:8] CTE_MODE — RF front-end CTE_MODE input selection
    0=RF_CTE_MODE_SRC_GPIO_0 (Select GPIO[0] as source); 1=RF_CTE_MODE_SRC_GPIO_1 (Select GPIO[1] as source); 2=RF_CTE_MODE_SRC_GPIO_2 (Select GPIO[5] as source); {v}=RF_CTE_MODE_SRC_GPIO_{v} (Select GPIO[{v}] as source) (v=3..15); 16=RF_CTE_MODE_SRC_CONST_LOW (Select constant low as source); 17=RF_CTE_MODE_SRC_CONST_HIGH (Select constant high as source); 18=RF_CTE_MODE_SRC_BB_CTE_MODE (Select baseband CTE_MODE as source)
  [4:0] CTE_SAMPLE_P — RF front-end CTE_SAMPLE_P input selection
    0=RF_CTE_SAMPLE_P_SRC_GPIO_0 (Select GPIO[0] as source); 1=RF_CTE_SAMPLE_P_SRC_GPIO_1 (Select GPIO[1] as source); 2=RF_CTE_SAMPLE_P_SRC_GPIO_2 (Select GPIO[5] as source); {v}=RF_CTE_SAMPLE_P_SRC_GPIO_{v} (Select GPIO[{v}] as source) (v=3..15); 16=RF_CTE_SAMPLE_P_SRC_CONST_LOW (Select constant low as source); 17=RF_CTE_SAMPLE_P_SRC_CONST_HIGH (Select constant high as source); 18=RF_CTE_SAMPLE_P_SRC_BB_CTE_MODE (Select baseband CTE_SAMPLE_P as source)
0x13C GPIO_SRC_ASCC reset 0x1010 — ASCC Interface Input Selection
  [12:8] ASYNC_CLOCK — ASCC asynchronous clock source input selection
    0=ASCC_ASYNC_CLOCK_SRC_GPIO_0 (Select GPIO[0] as source); 1=ASCC_ASYNC_CLOCK_SRC_GPIO_1 (Select GPIO[1] as source); 2=ASCC_ASYNC_CLOCK_SRC_GPIO_2 (Select GPIO[5] as source); {v}=ASCC_ASYNC_CLOCK_SRC_GPIO_{v} (Select GPIO[{v}] as source) (v=3..15); 16=ASCC_ASYNC_CLOCK_SRC_CONST_LOW (Select constant low as source); 17=ASCC_ASYNC_CLOCK_SRC_CONST_HIGH (Select constant high as source); 18=ASCC_ASYNC_CLOCK_SRC_STANDBYCLK (Select STANDBYCLK as source)
  [4:0] SYNC_PULSE — ASCC synchronization pulse input selection
    0=ASCC_SYNC_PULSE_SRC_GPIO_0 (Select GPIO[0] as source); 1=ASCC_SYNC_PULSE_SRC_GPIO_1 (Select GPIO[1] as source); 2=ASCC_SYNC_PULSE_SRC_GPIO_2 (Select GPIO[5] as source); {v}=ASCC_SYNC_PULSE_SRC_GPIO_{v} (Select GPIO[{v}] as source) (v=3..15); 16=ASCC_SYNC_PULSE_SRC_CONST_LOW (Select constant low as source); 17=ASCC_SYNC_PULSE_SRC_CONST_HIGH (Select constant high as source)
{0x20000+4i} GPIO_CFG_NS[{i}] (i=0..15) access not given reset not defined — Digital IO Configuration
0x20040 GPIO_INPUT_DATA_NS access not given reset not defined — Digital IOs Input Data State
0x20044 GPIO_OUTPUT_DATA_NS access not given reset not defined — GPIO Output Data Register
0x20048 GPIO_OUTPUT_DATA_SET_NS access not given reset not defined — GPIO Output Data Set
0x2004C GPIO_OUTPUT_DATA_CLR_NS access not given reset not defined — GPIO Output Data Clear
0x20050 GPIO_DIR_NS access not given reset not defined — Digital IOs Direction State
0x20054 GPIO_MODE_NS access not given reset not defined — Digital IOs Mode State
{0x20058+4i} GPIO_INT_CFG_NS[{i}] (i=0..3) access not given reset not defined — GPIO Interrupt Configuration
{0x2006C+4i} GPIO_INT_STATUS_NS[{i}] (i=0..3) access not given reset not defined — GPIO Interrupt Status
